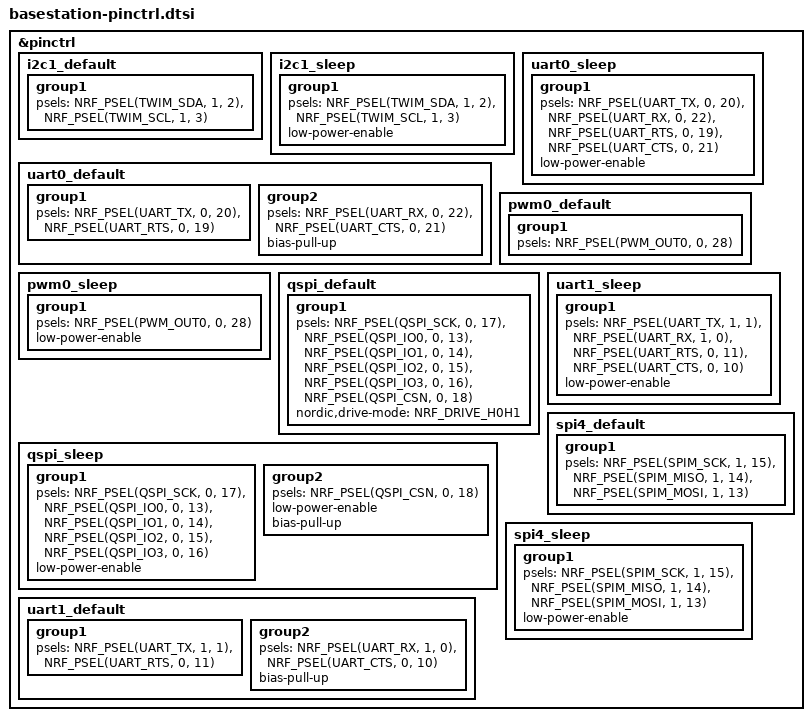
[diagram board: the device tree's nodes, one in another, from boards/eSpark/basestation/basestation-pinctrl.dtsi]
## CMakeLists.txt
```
#
# Copyright (c) 2018 Nordic Semiconductor
#
# SPDX-License-Identifier: LicenseRef-Nordic-5-Clause
#
cmake_minimum_required(VERSION 3.20.0)

find_package(Zephyr REQUIRED HINTS $ENV{ZEPHYR_BASE})
project(BaseStation-Board)

# NORDIC SDK APP START
target_sources(app PRIVATE
  src/main.c
)

# NORDIC SDK APP END
```

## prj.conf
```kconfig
#
# Copyright (c) 2018 Nordic Semiconductor
#
# SPDX-License-Identifier: LicenseRef-Nordic-5-Clause
#

# Config logger
CONFIG_LOG=y
CONFIG_USE_SEGGER_RTT=y
CONFIG_LOG_BACKEND_RTT=y
CONFIG_LOG_BACKEND_UART=n
CONFIG_LOG_PRINTK=n
# CONFIG_LOG_BACKEND_RTT_MODE_DROP=y
CONFIG_LOG_BACKEND_RTT_MODE_OVERWRITE=y

# Make sure printk is printing to the UART console
CONFIG_CONSOLE=y
CONFIG_UART_CONSOLE=n

# Enable the UART driver
CONFIG_SERIAL=y
CONFIG_UART_ASYNC_API=y
CONFIG_NRFX_UARTE0=y

CONFIG_GPIO=y

CONFIG_HEAP_MEM_POOL_SIZE=2048

CONFIG_BT=y
CONFIG_BT_PERIPHERAL=y
CONFIG_BT_DEVICE_NAME="Nordic_UART_Service"
CONFIG_BT_MAX_CONN=1
CONFIG_BT_MAX_PAIRED=1

# Enable the NUS service
CONFIG_BT_NUS=y

# Enable bonding
CONFIG_BT_SETTINGS=y
CONFIG_FLASH=y
CONFIG_FLASH_PAGE_LAYOUT=y
CONFIG_FLASH_MAP=y

# This example requires more stack
CONFIG_MAIN_STACK_SIZE=1152
CONFIG_SYSTEM_WORKQUEUE_STACK_SIZE=2048

CONFIG_ASSERT=y

CONFIG_CLOCK_CONTROL_NRF_K32SRC_RC=y
CONFIG_BT_BUF_ACL_RX_SIZE=251
CONFIG_BT_BUF_ACL_TX_SIZE=251
CONFIG_BT_L2CAP_TX_MTU=247
CONFIG_BT_CTLR_DATA_LENGTH_MAX=251
```

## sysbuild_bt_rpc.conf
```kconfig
#
# Copyright (c) 2024 Nordic Semiconductor
#
# SPDX-License-Identifier: LicenseRef-Nordic-5-Clause
#

SB_CONFIG_NETCORE_IPC_RADIO_BT_RPC=n
SB_CONFIG_NETCORE_IPC_RADIO_BT_HCI_IPC=y
```

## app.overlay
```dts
/*
 * Copyright (c) 2022 Nordic Semiconductor ASA
 *
 * SPDX-License-Identifier: LicenseRef-Nordic-5-Clause
 */

&pinctrl {
    ble_default: ble_default {
        group1 {
            psels = <NRF_PSEL(UART_TX, 1, 6)>,
                    <NRF_PSEL(UART_RTS, 0, 19)>;
        };
        group2 {
            psels = <NRF_PSEL(UART_RX, 1, 8)>,
                    <NRF_PSEL(UART_CTS, 0, 21)>;
            bias-pull-up;
        };
    };

    ble_sleep: ble_sleep {
        group1 {
            psels = <NRF_PSEL(UART_TX, 1, 6)>,
                    <NRF_PSEL(UART_RX, 1, 8)>,
                    <NRF_PSEL(UART_RTS, 0, 19)>,
                    <NRF_PSEL(UART_CTS, 0, 21)>;
            low-power-enable;
        };
    };
};

/ {

    chosen {
        zephyr,console = &uart0;
        zephyr,shell-uart = &uart0;
        zephyr,uart-mcumgr = &uart0;
        zephyr,bt-mon-uart = &uart0;
        zephyr,bt-c2h-uart = &uart0;
        zephyr,bt-hci = &bt_hci_ipc0;
        nordic,802154-spinel-ipc = &ipc0;
        zephyr,ieee802154 = &ieee802154;
        nordic,nus-uart = &uart0;
    };
};

&uart0 {
    status = "okay";
    current-speed = <115200>;
    pinctrl-0 = <&ble_default>;
    pinctrl-1 = <&ble_sleep>;
    pinctrl-names = "default", "sleep";
};

&vregmain {
    regulator-initial-mode = <NRF5X_REG_MODE_LDO>;
};

&vregradio {
    regulator-initial-mode = <NRF5X_REG_MODE_LDO>;
};

&vregh {
    status = "disabled";
};
```

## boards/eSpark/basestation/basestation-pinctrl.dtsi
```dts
&pinctrl {
    i2c1_default: i2c1_default {
		group1 {
			psels = <NRF_PSEL(TWIM_SDA, 1, 2)>,
				<NRF_PSEL(TWIM_SCL, 1, 3)>;
		};
	};

	i2c1_sleep: i2c1_sleep {
		group1 {
			psels = <NRF_PSEL(TWIM_SDA, 1, 2)>,
				<NRF_PSEL(TWIM_SCL, 1, 3)>;
			low-power-enable;
		};
	};

	uart0_default: uart0_default {
		group1 {
			psels = <NRF_PSEL(UART_TX, 0, 20)>,
				<NRF_PSEL(UART_RTS, 0, 19)>;
		};
		group2 {
			psels = <NRF_PSEL(UART_RX, 0, 22)>,
				<NRF_PSEL(UART_CTS, 0, 21)>;
			bias-pull-up;
		};
	};

	uart0_sleep: uart0_sleep {
		group1 {
			psels = <NRF_PSEL(UART_TX, 0, 20)>,
				<NRF_PSEL(UART_RX, 0, 22)>,
				<NRF_PSEL(UART_RTS, 0, 19)>,
				<NRF_PSEL(UART_CTS, 0, 21)>;
			low-power-enable;
		};
	};

	pwm0_default: pwm0_default {
		group1 {
			psels = <NRF_PSEL(PWM_OUT0, 0, 28)>;
		};
	};

	pwm0_sleep: pwm0_sleep {
		group1 {
			psels = <NRF_PSEL(PWM_OUT0, 0, 28)>;
			low-power-enable;
		};
	};

	qspi_default: qspi_default {
		group1 {
			psels = <NRF_PSEL(QSPI_SCK, 0, 17)>,
				<NRF_PSEL(QSPI_IO0, 0, 13)>,
				<NRF_PSEL(QSPI_IO1, 0, 14)>,
				<NRF_PSEL(QSPI_IO2, 0, 15)>,
				<NRF_PSEL(QSPI_IO3, 0, 16)>,
				<NRF_PSEL(QSPI_CSN, 0, 18)>;
			nordic,drive-mode = <NRF_DRIVE_H0H1>;
		};
	};

	qspi_sleep: qspi_sleep {
		group1 {
			psels = <NRF_PSEL(QSPI_SCK, 0, 17)>,
				<NRF_PSEL(QSPI_IO0, 0, 13)>,
				<NRF_PSEL(QSPI_IO1, 0, 14)>,
				<NRF_PSEL(QSPI_IO2, 0, 15)>,
				<NRF_PSEL(QSPI_IO3, 0, 16)>;
			low-power-enable;
		};
		group2 {
			psels = <NRF_PSEL(QSPI_CSN, 0, 18)>;
			low-power-enable;
			bias-pull-up;
		};
	};

	uart1_default: uart1_default {
		group1 {
			psels = <NRF_PSEL(UART_TX, 1, 1)>,
				<NRF_PSEL(UART_RTS, 0, 11)>;
		};
		group2 {
			psels = <NRF_PSEL(UART_RX, 1, 0)>,
				<NRF_PSEL(UART_CTS, 0, 10)>;
			bias-pull-up;
		};
	};

	uart1_sleep: uart1_sleep {
		group1 {
			psels = <NRF_PSEL(UART_TX, 1, 1)>,
				<NRF_PSEL(UART_RX, 1, 0)>,
				<NRF_PSEL(UART_RTS, 0, 11)>,
				<NRF_PSEL(UART_CTS, 0, 10)>;
			low-power-enable;
		};
	};

	spi4_default: spi4_default {
		group1 {
			psels = <NRF_PSEL(SPIM_SCK, 1, 15)>,
				<NRF_PSEL(SPIM_MISO, 1, 14)>,
				<NRF_PSEL(SPIM_MOSI, 1, 13)>;
		};
	};

	spi4_sleep: spi4_sleep {
		group1 {
			psels = <NRF_PSEL(SPIM_SCK, 1, 15)>,
				<NRF_PSEL(SPIM_MISO, 1, 14)>,
				<NRF_PSEL(SPIM_MOSI, 1, 13)>;
			low-power-enable;
		};
	};
};
```

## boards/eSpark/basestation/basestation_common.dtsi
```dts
&gpiote {
	status = "okay";
};

&gpio0 {
	status = "okay";
};

&gpio1 {
	status = "okay";
};
```

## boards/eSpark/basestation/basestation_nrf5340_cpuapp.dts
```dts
/dts-v1/;
#include <nordic/nrf5340_cpuapp_qkaa.dtsi>
#include "basestation-pinctrl.dtsi"
#include "basestation_common.dtsi"

/ {
	model = "Custom Board auto generated by nRF Connect for VS Code (CPUAPP)";
	compatible = "eSpark,basestation-cpuapp";

	chosen {
		zephyr,sram = &sram0_image;
		zephyr,flash = &flash0;
		zephyr,code-partition = &slot0_partition;
		zephyr,sram-secure-partition = &sram0_s;
		zephyr,sram-non-secure-partition = &sram0_ns;
	};
};

#include "basestation-cpuapp_partitioning.dtsi"
#include "basestation-shared_sram.dtsi"
```

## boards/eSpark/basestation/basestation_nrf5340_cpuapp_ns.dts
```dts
/dts-v1/;
#include <nordic/nrf5340_cpuappns_qkaa.dtsi>
#include "basestation-pinctrl.dtsi"
#include "basestation_common.dtsi"

/ {
	model = "Custom Board auto generated by nRF Connect for VS Code (CPUAPP Non-Secure)";
	compatible = "eSpark,basestation-cpuapp-ns";

	chosen {
		zephyr,sram = &sram0_ns;
		zephyr,flash = &flash0;
		zephyr,code-partition = &slot0_ns_partition;
	};
};

#include "basestation-cpuapp_partitioning.dtsi"
#include "basestation-shared_sram.dtsi"
```

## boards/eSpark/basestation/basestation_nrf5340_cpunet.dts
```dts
/dts-v1/;
#include <nordic/nrf5340_cpunet_qkaa.dtsi>
#include "basestation-pinctrl.dtsi"
#include "basestation_common.dtsi"

/ {
	model = "Custom Board auto generated by nRF Connect for VS Code";
	compatible = "eSpark,basestation-cpunet";

	chosen {
		zephyr,sram = &sram1;
		zephyr,flash = &flash1;
		zephyr,code-partition = &slot0_partition;
	};
};

&flash1 {
	partitions {
		compatible = "fixed-partitions";
		#address-cells = <1>;
		#size-cells = <1>;

		boot_partition: partition@0 {
			label = "mcuboot";
			reg = <0x00000000 DT_SIZE_K(48)>;
		};

		slot0_partition: partition@c000 {
			label = "image-0";
			reg = <0x0000c000 DT_SIZE_K(92)>;
		};

		slot1_partition: partition@23000 {
			label = "image-1";
			reg = <0x00023000 DT_SIZE_K(92)>;
		};

		storage_partition: partition@3a000 {
			label = "storage";
			reg = <0x0003a000 DT_SIZE_K(24)>;
		};
	};
};

#include "basestation-shared_sram.dtsi"
```

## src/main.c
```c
/*
 * Copyright (c) 2018 Nordic Semiconductor ASA
 *
 * SPDX-License-Identifier: LicenseRef-Nordic-5-Clause
 */

/** @file
 *  @brief Nordic UART Bridge Service (NUS) sample
 */
#include <uart_async_adapter.h>

#include <zephyr/types.h>
#include <zephyr/kernel.h>
#include <zephyr/drivers/uart.h>
#include <zephyr/usb/usb_device.h>

#include <zephyr/device.h>
#include <zephyr/devicetree.h>
#include <soc.h>

#include <zephyr/bluetooth/bluetooth.h>
#include <zephyr/bluetooth/uuid.h>
#include <zephyr/bluetooth/gatt.h>
#include <zephyr/bluetooth/hci.h>

#include <bluetooth/services/nus.h>

#include <zephyr/settings/settings.h>

#include <stdio.h>
#include <string.h>

#include <zephyr/logging/log.h>

#include <nrfx.h>  // or <nrf.h>

#define LOG_MODULE_NAME peripheral_uart
LOG_MODULE_REGISTER(LOG_MODULE_NAME);

#define STACKSIZE CONFIG_BT_NUS_THREAD_STACK_SIZE
#define PRIORITY 7

#define DEVICE_NAME CONFIG_BT_DEVICE_NAME
#define DEVICE_NAME_LEN	(sizeof(DEVICE_NAME) - 1)

#define RUN_LED_BLINK_INTERVAL 1000

#define UART_BUF_SIZE 64 // CONFIG_BT_NUS_UART_BUFFER_SIZE
#define UART_WAIT_FOR_BUF_DELAY K_MSEC(50)
#define UART_WAIT_FOR_RX CONFIG_BT_NUS_UART_RX_WAIT_TIME

#define FRAME_HEADER 0xAA  // Example header byte
#define FRAME_FOOTER 0x55  // Example footer byte

static K_SEM_DEFINE(ble_init_ok, 0, 1);

static struct bt_conn *current_conn;
static struct bt_conn *auth_conn;

static const struct device *uart = DEVICE_DT_GET(DT_CHOSEN(nordic_nus_uart));
static struct k_work_delayable uart_work;

struct uart_data_t {
	void *fifo_reserved;
	uint8_t data[UART_BUF_SIZE];
	uint16_t len;
};

static K_FIFO_DEFINE(fifo_uart_tx_data);
static K_FIFO_DEFINE(fifo_uart_rx_data);

static const struct bt_data ad[] = {
	BT_DATA_BYTES(BT_DATA_FLAGS, (BT_LE_AD_GENERAL | BT_LE_AD_NO_BREDR)),
	BT_DATA(BT_DATA_NAME_COMPLETE, DEVICE_NAME, DEVICE_NAME_LEN),
};

static const struct bt_data sd[] = {
	BT_DATA_BYTES(BT_DATA_UUID128_ALL, BT_UUID_NUS_VAL),
};

#ifdef CONFIG_UART_ASYNC_ADAPTER
UART_ASYNC_ADAPTER_INST_DEFINE(async_adapter);
#else
#define async_adapter NULL
#endif

static void uart_cb(const struct device *dev, struct uart_event *evt, void *user_data)
{
	ARG_UNUSED(dev);

	static size_t aborted_len;
	struct uart_data_t *buf;
	static uint8_t *aborted_buf;
	static bool disable_req;

	static bool frame_in_progress = false;
	static struct uart_data_t *frame_buf = NULL;

	switch (evt->type) {
	case UART_TX_DONE:
		LOG_DBG("UART_TX_DONE");
		if ((evt->data.tx.len == 0) ||
		    (!evt->data.tx.buf)) {
			return;
		}

		if (aborted_buf) {
			buf = CONTAINER_OF(aborted_buf, struct uart_data_t,
					   data[0]);
			aborted_buf = NULL;
			aborted_len = 0;
		} else {
			buf = CONTAINER_OF(evt->data.tx.buf, struct uart_data_t,
					   data[0]);
		}

		k_free(buf);

		buf = k_fifo_get(&fifo_uart_tx_data, K_NO_WAIT);
		if (!buf) {
			return;
		}

		if (uart_tx(uart, buf->data, buf->len, SYS_FOREVER_MS)) {
			LOG_WRN("Failed to send data over UART");
		}

		break;

	case UART_RX_RDY:
		LOG_DBG("UART_RX_RDY");
		// buf = CONTAINER_OF(evt->data.rx.buf, struct uart_data_t, data[0]);
		// buf->len += evt->data.rx.len;

		for (int i = 0; i < evt->data.rx.len; i++) {
			uint8_t byte = evt->data.rx.buf[evt->data.rx.offset + i];

			if (!frame_in_progress) {
				if (byte == FRAME_HEADER) {
					frame_buf = k_malloc(sizeof(struct uart_data_t));
					if (frame_buf) {
						frame_buf->len = 0;
						frame_in_progress = true;
					} else {
						LOG_WRN("Could not allocate frame buffer");
					}
				}
			} else {
				// Frame in progress
				if (byte == FRAME_FOOTER) {
					// End of frame
					if (frame_buf->len > 0) {
						k_fifo_put(&fifo_uart_rx_data, frame_buf);
					} else {
						k_free(frame_buf);  // Empty frame
					}
					frame_buf = NULL;
					frame_in_progress = false;
				} else {
					if (frame_buf->len < sizeof(frame_buf->data)) {
						frame_buf->data[frame_buf->len++] = byte;
					} else {
						LOG_WRN("Frame buffer overflow, discarding");
						k_free(frame_buf);
						frame_buf = NULL;
						frame_in_progress = false;
					}
				}
			}
		}

		if (disable_req) {
			return;
		}

		if ((evt->data.rx.buf[buf->len - 1] == '\n') ||
		    (evt->data.rx.buf[buf->len - 1] == '\r')) {
			disable_req = true;
			uart_rx_disable(uart);
		}

		break;

	case UART_RX_DISABLED:
		LOG_DBG("UART_RX_DISABLED");
		disable_req = false;

		buf = k_malloc(sizeof(*buf));
		if (buf) {
			buf->len = 0;
		} else {
			LOG_WRN("Not able to allocate UART receive buffer");
			k_work_reschedule(&uart_work, UART_WAIT_FOR_BUF_DELAY);
			return;
		}

		uart_rx_enable(uart, buf->data, sizeof(buf->data),
			       UART_WAIT_FOR_RX);

		break;

	case UART_RX_BUF_REQUEST:
		LOG_DBG("UART_RX_BUF_REQUEST");
		buf = k_malloc(sizeof(*buf));
		if (buf) {
			buf->len = 0;
			uart_rx_buf_rsp(uart, buf->data, sizeof(buf->data));
		} else {
			LOG_WRN("Not able to allocate UART receive buffer");
		}

		break;

	case UART_RX_BUF_RELEASED:
		LOG_DBG("UART_RX_BUF_RELEASED");
		buf = CONTAINER_OF(evt->data.rx_buf.buf, struct uart_data_t,
				   data[0]);

		if (buf->len > 0) {
			k_fifo_put(&fifo_uart_rx_data, buf);
		} else {
			k_free(buf);
		}

		break;

	case UART_TX_ABORTED:
		LOG_DBG("UART_TX_ABORTED");
		if (!aborted_buf) {
			aborted_buf = (uint8_t *)evt->data.tx.buf;
		}

		aborted_len += evt->data.tx.len;
		buf = CONTAINER_OF((void *)aborted_buf, struct uart_data_t,
				   data);

		uart_tx(uart, &buf->data[aborted_len],
			buf->len - aborted_len, SYS_FOREVER_MS);

		break;

	default:
		break;
	}
}

static void uart_work_handler(struct k_work *item)
{
	struct uart_data_t *buf;

	buf = k_malloc(sizeof(*buf));
	if (buf) {
		buf->len = 0;
	} else {
		LOG_WRN("Not able to allocate UART receive buffer");
		k_work_reschedule(&uart_work, UART_WAIT_FOR_BUF_DELAY);
		return;
	}

	uart_rx_enable(uart, buf->data, sizeof(buf->data), UART_WAIT_FOR_RX);
}

static bool uart_test_async_api(const struct device *dev)
{
	const struct uart_driver_api *api =
			(const struct uart_driver_api *)dev->api;

	return (api->callback_set != NULL);
}

static int uart_init(void)
{
	int err;
	int pos;
	struct uart_data_t *rx;
	struct uart_data_t *tx;

	if (!device_is_ready(uart)) {
		return -ENODEV;
	}

	if (IS_ENABLED(CONFIG_USB_DEVICE_STACK)) {
		err = usb_enable(NULL);
		if (err && (err != -EALREADY)) {
			LOG_ERR("Failed to enable USB");
			return err;
		}
	}

	rx = k_malloc(sizeof(*rx));
	if (rx) {
		rx->len = 0;
	} else {
		return -ENOMEM;
	}

	k_work_init_delayable(&uart_work, uart_work_handler);


	if (IS_ENABLED(CONFIG_UART_ASYNC_ADAPTER) && !uart_test_async_api(uart)) {
		/* Implement API adapter */
		uart_async_adapter_init(async_adapter, uart);
		uart = async_adapter;
	}

	err = uart_callback_set(uart, uart_cb, NULL);
	if (err) {
		k_free(rx);
		LOG_ERR("Cannot initialize UART callback");
		return err;
	}

	if (IS_ENABLED(CONFIG_UART_LINE_CTRL)) {
		LOG_INF("Wait for DTR");
		while (true) {
			uint32_t dtr = 0;

			uart_line_ctrl_get(uart, UART_LINE_CTRL_DTR, &dtr);
			if (dtr) {
				break;
			}
			/* Give CPU resources to low priority threads. */
			k_sleep(K_MSEC(100));
		}
		LOG_INF("DTR set");
		err = uart_line_ctrl_set(uart, UART_LINE_CTRL_DCD, 1);
		if (err) {
			LOG_WRN("Failed to set DCD, ret code %d", err);
		}
		err = uart_line_ctrl_set(uart, UART_LINE_CTRL_DSR, 1);
		if (err) {
			LOG_WRN("Failed to set DSR, ret code %d", err);
		}
	}

	tx = k_malloc(sizeof(*tx));

	if (tx) {
        pos = 0;
		// pos = snprintf(tx->data, sizeof(tx->data),
		// 	       "Starting Nordic UART service example\r\n");

		if ((pos < 0) || (pos >= sizeof(tx->data))) {
			k_free(rx);
			k_free(tx);
			LOG_ERR("snprintf returned %d", pos);
			return -ENOMEM;
		}

		tx->len = pos;
	} else {
		k_free(rx);
		return -ENOMEM;
	}

	err = uart_tx(uart, tx->data, tx->len, SYS_FOREVER_MS);
	if (err) {
		k_free(rx);
		k_free(tx);
		LOG_ERR("Cannot display welcome message (err: %d)", err);
		return err;
	}

	err = uart_rx_enable(uart, rx->data, sizeof(rx->data), UART_WAIT_FOR_RX);
	if (err) {
		LOG_ERR("Cannot enable uart reception (err: %d)", err);
		/* Free the rx buffer only because the tx buffer will be handled in the callback */
		k_free(rx);
	}

	return err;
}

static void connected(struct bt_conn *conn, uint8_t err)
{
	char addr[BT_ADDR_LE_STR_LEN];

	if (err) {
		LOG_ERR("Connection failed, err 0x%02x %s", err, bt_hci_err_to_str(err));
		return;
	}

	bt_addr_le_to_str(bt_conn_get_dst(conn), addr, sizeof(addr));
	LOG_INF("Connected %s", addr);

	current_conn = bt_conn_ref(conn);
}

static void disconnected(struct bt_conn *conn, uint8_t reason)
{
	char addr[BT_ADDR_LE_STR_LEN];

	bt_addr_le_to_str(bt_conn_get_dst(conn), addr, sizeof(addr));

	LOG_INF("Disconnected: %s, reason 0x%02x %s", addr, reason, bt_hci_err_to_str(reason));

	if (auth_conn) {
		bt_conn_unref(auth_conn);
		auth_conn = NULL;
	}

	if (current_conn) {
		bt_conn_unref(current_conn);
		current_conn = NULL;
	}
}

#ifdef CONFIG_BT_NUS_SECURITY_ENABLED
static void security_changed(struct bt_conn *conn, bt_security_t level,
			     enum bt_security_err err)
{
	char addr[BT_ADDR_LE_STR_LEN];

	bt_addr_le_to_str(bt_conn_get_dst(conn), addr, sizeof(addr));

	if (!err) {
		LOG_INF("Security changed: %s level %u", addr, level);
	} else {
		LOG_WRN("Security failed: %s level %u err %d %s", addr, level, err,
			bt_security_err_to_str(err));
	}
}
#endif

BT_CONN_CB_DEFINE(conn_callbacks) = {
	.connected    = connected,
	.disconnected = disconnected,
#ifdef CONFIG_BT_NUS_SECURITY_ENABLED
	.security_changed = security_changed,
#endif
};

#if defined(CONFIG_BT_NUS_SECURITY_ENABLED)
static void auth_passkey_display(struct bt_conn *conn, unsigned int passkey)
{
	char addr[BT_ADDR_LE_STR_LEN];

	bt_addr_le_to_str(bt_conn_get_dst(conn), addr, sizeof(addr));

	LOG_INF("Passkey for %s: %06u", addr, passkey);
}

static void auth_passkey_confirm(struct bt_conn *conn, unsigned int passkey)
{
	char addr[BT_ADDR_LE_STR_LEN];

	auth_conn = bt_conn_ref(conn);

	bt_addr_le_to_str(bt_conn_get_dst(conn), addr, sizeof(addr));

	LOG_INF("Passkey for %s: %06u", addr, passkey);

	if (IS_ENABLED(CONFIG_SOC_SERIES_NRF54HX) || IS_ENABLED(CONFIG_SOC_SERIES_NRF54LX)) {
		LOG_INF("Press Button 0 to confirm, Button 1 to reject.");
	} else {
		LOG_INF("Press Button 1 to confirm, Button 2 to reject.");
	}
}


static void auth_cancel(struct bt_conn *conn)
{
	char addr[BT_ADDR_LE_STR_LEN];

	bt_addr_le_to_str(bt_conn_get_dst(conn), addr, sizeof(addr));

	LOG_INF("Pairing cancelled: %s", addr);
}


static void pairing_complete(struct bt_conn *conn, bool bonded)
{
	char addr[BT_ADDR_LE_STR_LEN];

	bt_addr_le_to_str(bt_conn_get_dst(conn), addr, sizeof(addr));

	LOG_INF("Pairing completed: %s, bonded: %d", addr, bonded);
}


static void pairing_failed(struct bt_conn *conn, enum bt_security_err reason)
{
	char addr[BT_ADDR_LE_STR_LEN];

	bt_addr_le_to_str(bt_conn_get_dst(conn), addr, sizeof(addr));

	LOG_INF("Pairing failed conn: %s, reason %d %s", addr, reason,
		bt_security_err_to_str(reason));
}

static struct bt_conn_auth_cb conn_auth_callbacks = {
	.passkey_display = auth_passkey_display,
	.passkey_confirm = auth_passkey_confirm,
	.cancel = auth_cancel,
};

static struct bt_conn_auth_info_cb conn_auth_info_callbacks = {
	.pairing_complete = pairing_complete,
	.pairing_failed = pairing_failed
};
#else
static struct bt_conn_auth_cb conn_auth_callbacks;
static struct bt_conn_auth_info_cb conn_auth_info_callbacks;
#endif

static void bt_receive_cb(struct bt_conn *conn, const uint8_t *const data,
			  uint16_t len)
{
	int err;
	char addr[BT_ADDR_LE_STR_LEN] = {0};

	bt_addr_le_to_str(bt_conn_get_dst(conn), addr, ARRAY_SIZE(addr));

	LOG_INF("Received data from: %s", addr);

	for (uint16_t pos = 0; pos != len;) {
		struct uart_data_t *tx = k_malloc(sizeof(*tx));

		if (!tx) {
			LOG_WRN("Not able to allocate UART send data buffer");
			return;
		}

		/* Keep the last byte of TX buffer for potential LF char. */
		size_t tx_data_size = sizeof(tx->data) - 1;

		if ((len - pos) > tx_data_size) {
			tx->len = tx_data_size;
		} else {
			tx->len = (len - pos);
		}

		memcpy(tx->data, &data[pos], tx->len);

		pos += tx->len;

		/* Append the LF character when the CR character triggered
		 * transmission from the peer.
		 */
		if ((pos == len) && (data[len - 1] == '\r')) {
			tx->data[tx->len] = '\n';
			tx->len++;
		}

		err = uart_tx(uart, tx->data, tx->len, SYS_FOREVER_MS);
		if (err) {
			k_fifo_put(&fifo_uart_tx_data, tx);
		}
	}
}

static struct bt_nus_cb nus_cb = {
	.received = bt_receive_cb,
};

void error(void)
{
	while (true) {
		/* Spin for ever */
		k_sleep(K_MSEC(1000));
	}
}

int main(void)
{
	int blink_status = 0;
	int err = 0;

	err = uart_init();
	if (err) {
		error();
	}

	if (IS_ENABLED(CONFIG_BT_NUS_SECURITY_ENABLED)) {
		err = bt_conn_auth_cb_register(&conn_auth_callbacks);
		if (err) {
			printk("Failed to register authorization callbacks.\n");
			return 0;
		}

		err = bt_conn_auth_info_cb_register(&conn_auth_info_callbacks);
		if (err) {
			printk("Failed to register authorization info callbacks.\n");
			return 0;
		}
	}

	err = bt_enable(NULL);
	if (err) {
		error();
	}

	LOG_INF("Bluetooth initialized BaseBoard");

	k_sem_give(&ble_init_ok);

	if (IS_ENABLED(CONFIG_SETTINGS)) {
		settings_load();
	}

	err = bt_nus_init(&nus_cb);
	if (err) {
		LOG_ERR("Failed to initialize UART service (err: %d)", err);
		return 0;
	}

	err = bt_le_adv_start(BT_LE_ADV_CONN, ad, ARRAY_SIZE(ad), sd,
			      ARRAY_SIZE(sd));
	if (err) {
		LOG_ERR("Advertising failed to start (err %d)", err);
		return 0;
	}

	for (;;) {
		k_sleep(K_MSEC(RUN_LED_BLINK_INTERVAL));
	}
}

void ble_write_thread(void)
{
	/* Don't go any further until BLE is initialized */
	k_sem_take(&ble_init_ok, K_FOREVER);
	struct uart_data_t nus_data = {
		.len = 0,
	};

	for (;;) {
		/* Wait indefinitely for data to be sent over bluetooth */
		struct uart_data_t *buf = k_fifo_get(&fifo_uart_rx_data,
						     K_FOREVER);

		int plen = MIN(sizeof(nus_data.data) - nus_data.len, buf->len);
		int loc = 0;

		while (plen > 0) {
			memcpy(&nus_data.data[nus_data.len], &buf->data[loc], plen);
			nus_data.len += plen;
			loc += plen;

			if (nus_data.len >= sizeof(nus_data.data) ||
			   (nus_data.data[nus_data.len - 1] == '\n') ||
			   (nus_data.data[nus_data.len - 1] == '\r')) {
				if (bt_nus_send(NULL, nus_data.data, nus_data.len)) {
					LOG_WRN("Failed to send data over BLE connection");
				}
				nus_data.len = 0;
			}

			plen = MIN(sizeof(nus_data.data), buf->len - loc);
		}

		k_free(buf);
	}
}

K_THREAD_DEFINE(ble_write_thread_id, STACKSIZE, ble_write_thread, NULL, NULL,
		NULL, PRIORITY, 0, 0);
```
